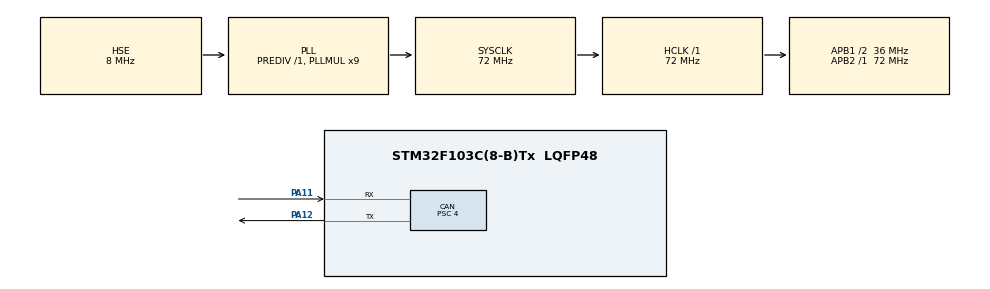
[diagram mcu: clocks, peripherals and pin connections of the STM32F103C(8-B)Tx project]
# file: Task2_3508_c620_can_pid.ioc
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CAN.BS1=CAN_BS1_6TQ
CAN.BS2=CAN_BS2_2TQ
CAN.CalculateBaudRate=1000000
CAN.CalculateTimeBit=1000
CAN.CalculateTimeQuantum=111.11111111111111
CAN.Prescaler=4
Mcu.Family=STM32F1
Mcu.Name=STM32F103C(8-B)Tx
Mcu.Package=LQFP48
NVIC.CAN1_RX1_IRQn=true\:0\:0\:false\:false\:true\:true\:true\:true
NVIC.PriorityGroup=NVIC_PRIORITYGROUP_4
NVIC.USB_HP_CAN1_TX_IRQn=true\:0\:0\:false\:false\:true\:true\:true\:true
NVIC.USB_LP_CAN1_RX0_IRQn=true\:0\:0\:false\:false\:true\:true\:true\:true
PA11.Mode=CAN_Activate
PA11.Signal=CAN_RX
PA12.Mode=CAN_Activate
PA12.Signal=CAN_TX
PA13.Mode=Serial_Wire
PA13.Signal=SYS_JTMS-SWDIO
PA14.Mode=Serial_Wire
PA14.Signal=SYS_JTCK-SWCLK
PD0-OSC_IN.Mode=HSE-External-Oscillator
PD0-OSC_IN.Signal=RCC_OSC_IN
PD1-OSC_OUT.Mode=HSE-External-Oscillator
PD1-OSC_OUT.Signal=RCC_OSC_OUT
ProjectManager.HeapSize=0x200
ProjectManager.StackSize=0x400
ProjectManager.TargetToolchain=MDK-ARM V5.32
RCC.AHBFreq_Value=72000000
RCC.APB1CLKDivider=RCC_HCLK_DIV2
RCC.APB1Freq_Value=36000000
RCC.APB1TimFreq_Value=72000000
RCC.APB2Freq_Value=72000000
RCC.APB2TimFreq_Value=72000000
RCC.HCLKFreq_Value=72000000
RCC.PLLMUL=RCC_PLL_MUL9
RCC.PLLSourceVirtual=RCC_PLLSOURCE_HSE
RCC.SYSCLKFreq_VALUE=72000000
RCC.SYSCLKSource=RCC_SYSCLKSOURCE_PLLCLK
RCC.USBFreq_Value=72000000
board=custom

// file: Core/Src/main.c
/* USER CODE BEGIN Header */
/**
 ******************************************************************************
 * @file           : main.c
 * @brief          : Main program body
 ******************************************************************************
 * @attention
 *
 * Copyright (c) 2025 STMicroelectronics.
 * All rights reserved.
 *
 * This software is licensed under terms that can be found in the LICENSE file
 * in the root directory of this software component.
 * If no LICENSE file comes with this software, it is provided AS-IS.
 *
 ******************************************************************************
 */
/* USER CODE END Header */
#include "main.h"
#include "can.h"
#include "gpio.h"

/* USER CODE BEGIN Includes */
#include "CAN_receive.h"
#include "bsp_can.h"
#include "pid.h"
#include "angle-pid.h"

/* USER CODE END Includes */

void SystemClock_Config(void);

/* USER CODE BEGIN 0 */
  uint8_t stage = 0;  //三种模式
  pid_type_def motor1_pid,motor1_angle_pid;
	fp32 yaw_angle;
	int ecd_sum=0; //motor1 ecd count sum
	int set_speed=0;
	fp32 set_angle=0;
	fp32 pid_k[3]={20,0.3,0};  //motor1 kp ki kd
	fp32 pid_angle_k[3]={90,0,0};
	motor_measure_t *motor1_data;
	int n=0;
/* USER CODE END 0 */

int main(void) {

    /* USER CODE BEGIN 1 */

		PID_init(&motor1_pid ,PID_POSITION,pid_k,16000,2000);  //PID的初始化
		PID_init(&motor1_angle_pid,PID_POSITION,pid_angle_k,1500,0);//set angle_pid para

    /* USER CODE END 1 */

    /* MCU Configuration--------------------------------------------------------*/

    /* Reset of all peripherals, Initializes the Flash interface and the Systick. */
    HAL_Init();

    /* Configure the system clock */
    SystemClock_Config();

    /* Initialize all configured peripherals */
    MX_GPIO_Init();
    MX_CAN_Init();
    /* USER CODE BEGIN 2 */
    can_filter_init();

    /* USER CODE END 2 */

    /* Infinite loop */
    /* USER CODE BEGIN WHILE */
    while (1) {

                switch (stage)
							{
                case 0:
										motor1_data=get_chassis_motor_measure_point(0);
										set_angle=pi;
										motor1_data->angle=angle_calc(); //get the motor angle
										PID_calc(&motor1_angle_pid,motor1_data->angle,set_angle);//calculate angle(pi)
										set_speed=motor1_angle_pid.out;//angle_pid_out as the current to motor1_speed
										PID_calc(&motor1_pid ,motor1_data->speed_rpm,set_speed);   //计算pid的返回值
										CAN_cmd_chassis(motor1_pid.Pout,0,0,0);

                    break;
                case 1:
										motor1_data=get_chassis_motor_measure_point(0);  //拿回电机1的数据
										set_angle=pi*3/2;
										motor1_data->angle=angle_calc(); //get the motor angle
										PID_calc(&motor1_angle_pid,motor1_data->angle,set_angle);//calculate angle(pi)
										set_speed =motor1_angle_pid.out;//angle_pid_out as the current to motor1_speed
										PID_calc(&motor1_pid ,motor1_data->speed_rpm,set_speed);   //计算pid的返回值
										CAN_cmd_chassis(motor1_pid.Pout,0,0,0);

                    break;
                case 2:
										motor1_data=get_chassis_motor_measure_point(0);  //拿回电机1的数据
										set_angle=2*pi;
										motor1_data->angle=angle_calc(); //get the motor angle
										PID_calc(&motor1_angle_pid,motor1_data->angle,set_angle);//calculate angle(pi)
										set_speed =motor1_angle_pid.out;//angle_pid_out as the current to motor1_speed
										PID_calc(&motor1_pid ,motor1_data->speed_rpm,set_speed);   //计算pid的返回值
										CAN_cmd_chassis(motor1_pid.Pout,0,0,0);

                    break;
                default:
                    break;

            }
								HAL_Delay(2);

        /* USER CODE END WHILE */

    }
}

void SystemClock_Config(void) {
    RCC_OscInitTypeDef RCC_OscInitStruct = {0};
    RCC_ClkInitTypeDef RCC_ClkInitStruct = {0};

    /** Initializes the RCC Oscillators according to the specified parameters
     * in the RCC_OscInitTypeDef structure.
     */
    RCC_OscInitStruct.OscillatorType = RCC_OSCILLATORTYPE_HSE;
    RCC_OscInitStruct.HSEState = RCC_HSE_ON;
    RCC_OscInitStruct.HSEPredivValue = RCC_HSE_PREDIV_DIV1;
    RCC_OscInitStruct.HSIState = RCC_HSI_ON;
    RCC_OscInitStruct.PLL.PLLState = RCC_PLL_ON;
    RCC_OscInitStruct.PLL.PLLSource = RCC_PLLSOURCE_HSE;
    RCC_OscInitStruct.PLL.PLLMUL = RCC_PLL_MUL9;
    if (HAL_RCC_OscConfig(&RCC_OscInitStruct) != HAL_OK) {
        Error_Handler();
    }

    /** Initializes the CPU, AHB and APB buses clocks
     */
    RCC_ClkInitStruct.ClockType = RCC_CLOCKTYPE_HCLK | RCC_CLOCKTYPE_SYSCLK | RCC_CLOCKTYPE_PCLK1 | RCC_CLOCKTYPE_PCLK2;
    RCC_ClkInitStruct.SYSCLKSource = RCC_SYSCLKSOURCE_PLLCLK;
    RCC_ClkInitStruct.AHBCLKDivider = RCC_SYSCLK_DIV1;
    RCC_ClkInitStruct.APB1CLKDivider = RCC_HCLK_DIV2;
    RCC_ClkInitStruct.APB2CLKDivider = RCC_HCLK_DIV1;

    if (HAL_RCC_ClockConfig(&RCC_ClkInitStruct, FLASH_LATENCY_2) != HAL_OK) {
        Error_Handler();
    }
}

void Error_Handler(void) {
    __disable_irq();
    while (1) {
    }
}
